# CH572SFR register map
Vendor: WCH Ltd.; Series: CH572; File version: 1.1
CPU: RISC-V r0p0, little endian, no MPU, no FPU, 2 interrupt priority bits
Registers are 32-bit, read-write, reset 0x0 unless marked. A register's access mark holds for its fields unless they carry their own. Offsets are from the block's base; [hi:lo] are bit positions.

## SPI
Base 0x40004000
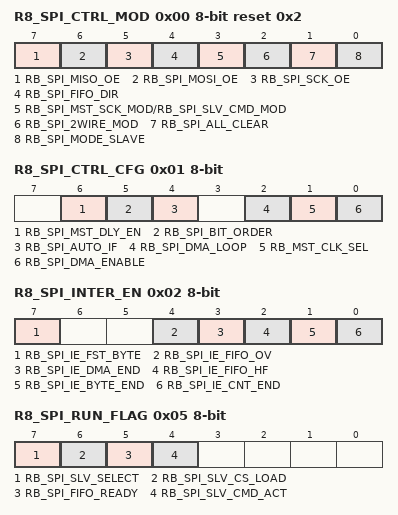
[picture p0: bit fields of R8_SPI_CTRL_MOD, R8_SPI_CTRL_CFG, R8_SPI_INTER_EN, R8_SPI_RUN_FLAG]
0x00 R8_SPI_CTRL_MOD 8-bit reset 0x2 — RW, SPI mode control
  [7] RB_SPI_MISO_OE — RW, SPI MISO output enable
  [6] RB_SPI_MOSI_OE — RW, SPI MOSI output enable
  [5] RB_SPI_SCK_OE — RW, SPI SCK output enable
  [4] RB_SPI_FIFO_DIR — RW, SPI FIFO direction: 0=out(write @master mode), 1=in(read @master mode)
  [3] RB_SPI_MST_SCK_MOD/RB_SPI_SLV_CMD_MOD — RW, SPI master clock mode: 0=mode 0, 1=mode 3;RW, SPI slave command mode: 0=byte stream, 1=first byte command
  [2] RB_SPI_2WIRE_MOD — RW, SPI enable 2 wire mode for slave: 0=3wire(SCK0,MOSI,MISO), 1=2wire(SCK0,MISO=MXSX)
  [1] RB_SPI_ALL_CLEAR — RW, force clear SPI FIFO and count
  [0] RB_SPI_MODE_SLAVE — RW, SPI slave mode: 0=master or host, 1=slave or device
0x01 R8_SPI_CTRL_CFG 8-bit — RW, SPI configuration control
  [6] RB_SPI_MST_DLY_EN — RW, SPI master input delay enable
  [5] RB_SPI_BIT_ORDER — RW, SPI bit data order: 0=MSB first, 1=LSB first
  [4] RB_SPI_AUTO_IF — RW, enable buffer/FIFO accessing to auto clear RB_SPI_IF_BYTE_END interrupt flag
  [2] RB_SPI_DMA_LOOP — RW, SPI DMA address loop enable
  [1] RB_MST_CLK_SEL — RW, When RB_SPI-PODE_SLAVE=0, select the main clock polarity; When RB_SPI-PODE_SLAVE=1, select the input and output direction for the two-wire mode slave machine
  [0] RB_SPI_DMA_ENABLE — RW, SPI DMA enable
0x02 R8_SPI_INTER_EN 8-bit — RW, SPI interrupt enable
  [7] RB_SPI_IE_FST_BYTE — RW, enable interrupt for SPI slave mode first byte received
  [4] RB_SPI_IE_FIFO_OV — RW, enable interrupt for SPI FIFO overflow
  [3] RB_SPI_IE_DMA_END — RW, enable interrupt for SPI DMA completion
  [2] RB_SPI_IE_FIFO_HF — RW, enable interrupt for SPI FIFO half
  [1] RB_SPI_IE_BYTE_END — RW, enable interrupt for SPI byte exchanged
  [0] RB_SPI_IE_CNT_END — RW, enable interrupt for SPI total byte count end
0x03 R8_SPI_CLOCK_DIV/R8_SPI_SLAVE_PRE 8-bit reset 0x10 — RW, SPI master clock divisor;RW, SPI slave preset value
0x04 R8_SPI_BUFFER 8-bit reset not defined — RW, SPI data buffer
0x05 R8_SPI_RUN_FLAG 8-bit ro — RO, SPI work flag
  [7] RB_SPI_SLV_SELECT — RO, SPI slave selection status
  [6] RB_SPI_SLV_CS_LOAD — RO, SPI slave chip-select loading status
  [5] RB_SPI_FIFO_READY — RO, SPI FIFO ready status
  [4] RB_SPI_SLV_CMD_ACT — RO, SPI slave first byte or command flag
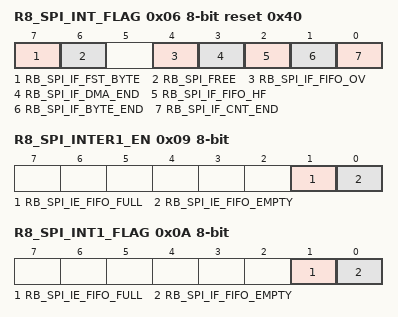
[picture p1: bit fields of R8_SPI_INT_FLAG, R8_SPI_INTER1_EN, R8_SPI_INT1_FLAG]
0x06 R8_SPI_INT_FLAG 8-bit reset 0x40 — RW1, SPI interrupt flag
  [7] RB_SPI_IF_FST_BYTE — RW1, interrupt flag for SPI slave mode first byte received
  [6] RB_SPI_FREE — RO, current SPI free status
  [4] RB_SPI_IF_FIFO_OV — RW1, interrupt flag for SPI FIFO overflow
  [3] RB_SPI_IF_DMA_END — RW1, interrupt flag for SPI DMA completion
  [2] RB_SPI_IF_FIFO_HF — RW1, interrupt flag for SPI FIFO half
  [1] RB_SPI_IF_BYTE_END — RW1, interrupt flag for SPI byte exchanged
  [0] RB_SPI_IF_CNT_END — RW1, interrupt flag for SPI total byte count end
0x07 R8_SPI_FIFO_COUNT 8-bit — RW, SPI FIFO count status
  [3:0] R8_SPI_FIFO_COUNT
0x08 R8_SPI_INT_TYPE 8-bit — RW, SPI interrupt trigger mode selection register
  [4:0] RB_SPI_INT_TYPE — RW, SPI interrupt trigger mode selection
0x09 R8_SPI_INTER1_EN 8-bit — RW, SPI Interrupt 1 Enable Register
  [1] RB_SPI_IE_FIFO_FULL — RW, Current FIFO data full interrupt enabled
  [0] RB_SPI_IE_FIFO_EMPTY — RW, Current FIFO data air break enable
0x0A R8_SPI_INT1_FLAG 8-bit — RW1, SPI interrupt 1 flag register
  [1] RB_SPI_IE_FIFO_FULL — RW1, Current FIFO data full flag
  [0] RB_SPI_IF_FIFO_EMPTY — RW1, Current FIFO data empty flag bit
0x0C R16_SPI_TOTAL_CNT 16-bit — RW, SPI total byte count, only low 12 bit
  [11:0] R16_SPI_TOTAL_CNT
0x10 R8_SPI_FIFO 8-bit reset not defined — RO/WO, SPI FIFO register
0x13 R8_SPI_FIFO_COUNT1 8-bit ro — RO, SPI FIFO count status
  [3:0] R8_SPI_FIFO_COUNT1
0x14 R32_SPI_DMA_NOW reset not defined — RW, SPI DMA current address
  [13:0] RB_SPI_DMA_NOW
0x18 R32_SPI_DMA_BEG reset not defined — RW, SPI DMA begin address
  [13:0] R32_SPI_DMA_BEG
0x1C R32_SPI_DMA_END reset not defined — RW, SPI DMA end address
  [13:0] R32_SPI_DMA_END
